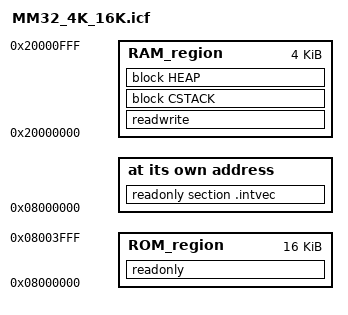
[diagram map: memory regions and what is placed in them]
/* - Vector Tables - */
define symbol __section_VECTOR_TABLE_BASE__ = 0x08000000;

/* - Memory Regions - */
define symbol __region_ROM_BASE__       = 0x08000000;
define symbol __region_ROM_SIZE__       = 0x4000;
define symbol __region_ROM_END__        = __region_ROM_BASE__ + __region_ROM_SIZE__ - 1;
define symbol __region_RAM_BASE__       = 0x20000000;
define symbol __region_RAM_SIZE__       = 0x1000;
define symbol __region_RAM_END__        = __region_RAM_BASE__ + __region_RAM_SIZE__ - 1;

/* - Stack & Heap Size - */
define symbol __CSTACK_SIZE_            = 0x400;
define symbol __HEAP_SIZE_              = 0x400;

/**** End of ICF editor section. ###ICF###*/

define memory mem   with size = 4G;
define region ROM_region      = mem:[from __region_ROM_BASE__ to __region_ROM_END__];
define region RAM_region      = mem:[from __region_RAM_BASE__ to __region_RAM_END__];

define block CSTACK with alignment = 8, size = __CSTACK_SIZE_ { };
define block HEAP   with alignment = 8, size = __HEAP_SIZE_   { };

initialize by copy { readwrite };
do not initialize  { section .noinit };

place at address mem: __section_VECTOR_TABLE_BASE__ { readonly section .intvec };

place in ROM_region   { readonly };
place in RAM_region   { readwrite, block CSTACK, block HEAP };

export symbol __region_RAM_BASE__;
export symbol __region_RAM_END__;
